# ESP32-P4 register map
Vendor: ESPRESSIF SYSTEMS (SHANGHAI) CO., LTD.; Series: ESP32 P-Series; File version: 3
CPU: RV32IMAFC r0p0, little endian, no MPU, FPU, 0 interrupt priority bits
Address unit: 32 bits
Registers are 32-bit, read-write, reset 0x0 unless marked. A register's access mark holds for its fields unless they carry their own. Offsets are from the block's base; [hi:lo] are bit positions; {n}, {i} and the like mark numbered series.

## INTERRUPT_CORE0 — Interrupt Controller (Core 0)
Base 0x500D6000
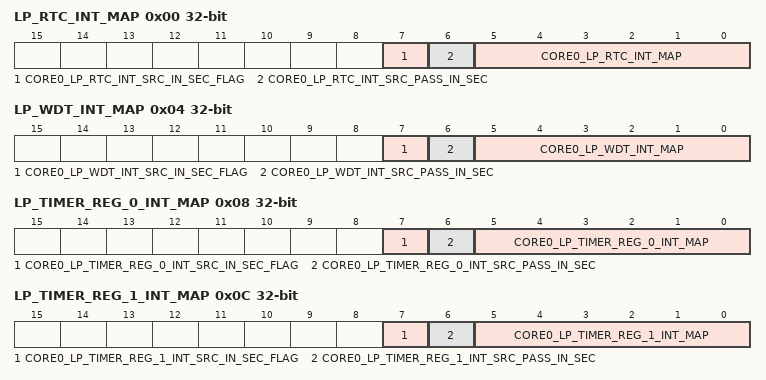
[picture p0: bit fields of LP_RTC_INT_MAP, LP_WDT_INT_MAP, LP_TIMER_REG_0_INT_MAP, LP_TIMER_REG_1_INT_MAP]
0x00 LP_RTC_INT_MAP
  [7] CORE0_LP_RTC_INT_SRC_IN_SEC_FLAG
  [6] CORE0_LP_RTC_INT_SRC_PASS_IN_SEC
  [5:0] CORE0_LP_RTC_INT_MAP — Configures the interrupt source into one CPU interrupt.
0x04 LP_WDT_INT_MAP
  [7] CORE0_LP_WDT_INT_SRC_IN_SEC_FLAG
  [6] CORE0_LP_WDT_INT_SRC_PASS_IN_SEC
  [5:0] CORE0_LP_WDT_INT_MAP — Configures the interrupt source into one CPU interrupt.
0x08 LP_TIMER_REG_0_INT_MAP
  [7] CORE0_LP_TIMER_REG_0_INT_SRC_IN_SEC_FLAG
  [6] CORE0_LP_TIMER_REG_0_INT_SRC_PASS_IN_SEC
  [5:0] CORE0_LP_TIMER_REG_0_INT_MAP — Configures the interrupt source into one CPU interrupt.
0x0C LP_TIMER_REG_1_INT_MAP
  [7] CORE0_LP_TIMER_REG_1_INT_SRC_IN_SEC_FLAG
  [6] CORE0_LP_TIMER_REG_1_INT_SRC_PASS_IN_SEC
  [5:0] CORE0_LP_TIMER_REG_1_INT_MAP — Configures the interrupt source into one CPU interrupt.
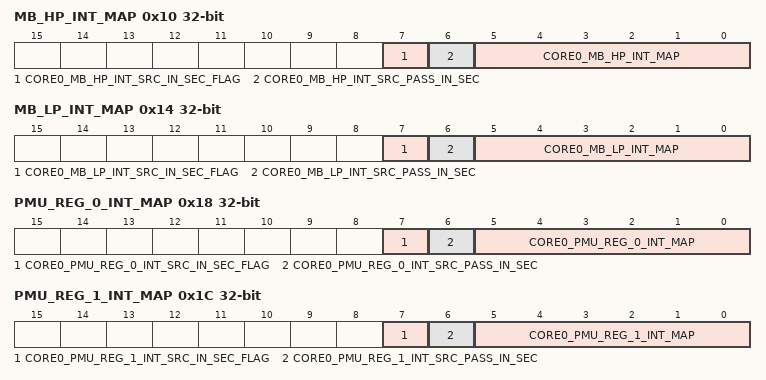
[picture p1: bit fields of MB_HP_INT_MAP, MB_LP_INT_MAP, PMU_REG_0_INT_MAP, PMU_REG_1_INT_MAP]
0x10 MB_HP_INT_MAP
  [7] CORE0_MB_HP_INT_SRC_IN_SEC_FLAG
  [6] CORE0_MB_HP_INT_SRC_PASS_IN_SEC
  [5:0] CORE0_MB_HP_INT_MAP — Configures the interrupt source into one CPU interrupt.
0x14 MB_LP_INT_MAP
  [7] CORE0_MB_LP_INT_SRC_IN_SEC_FLAG
  [6] CORE0_MB_LP_INT_SRC_PASS_IN_SEC
  [5:0] CORE0_MB_LP_INT_MAP — Configures the interrupt source into one CPU interrupt.
0x18 PMU_REG_0_INT_MAP
  [7] CORE0_PMU_REG_0_INT_SRC_IN_SEC_FLAG
  [6] CORE0_PMU_REG_0_INT_SRC_PASS_IN_SEC
  [5:0] CORE0_PMU_REG_0_INT_MAP — Configures the interrupt source into one CPU interrupt.
0x1C PMU_REG_1_INT_MAP
  [7] CORE0_PMU_REG_1_INT_SRC_IN_SEC_FLAG
  [6] CORE0_PMU_REG_1_INT_SRC_PASS_IN_SEC
  [5:0] CORE0_PMU_REG_1_INT_MAP — Configures the interrupt source into one CPU interrupt.
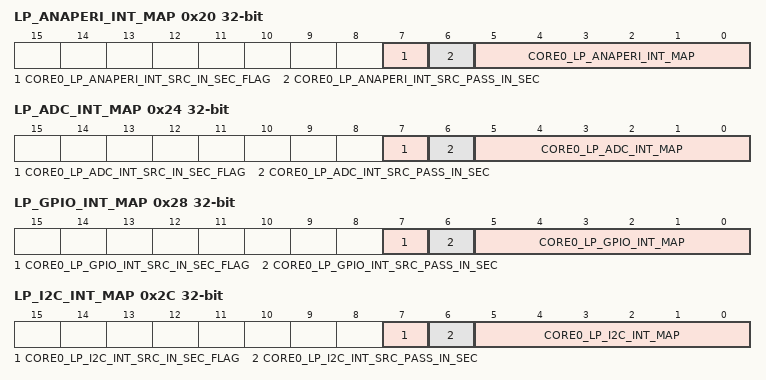
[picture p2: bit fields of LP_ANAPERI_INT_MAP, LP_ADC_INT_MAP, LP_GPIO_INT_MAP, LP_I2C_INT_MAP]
0x20 LP_ANAPERI_INT_MAP
  [7] CORE0_LP_ANAPERI_INT_SRC_IN_SEC_FLAG
  [6] CORE0_LP_ANAPERI_INT_SRC_PASS_IN_SEC
  [5:0] CORE0_LP_ANAPERI_INT_MAP — Configures the interrupt source into one CPU interrupt.
0x24 LP_ADC_INT_MAP
  [7] CORE0_LP_ADC_INT_SRC_IN_SEC_FLAG
  [6] CORE0_LP_ADC_INT_SRC_PASS_IN_SEC
  [5:0] CORE0_LP_ADC_INT_MAP — Configures the interrupt source into one CPU interrupt.
0x28 LP_GPIO_INT_MAP
  [7] CORE0_LP_GPIO_INT_SRC_IN_SEC_FLAG
  [6] CORE0_LP_GPIO_INT_SRC_PASS_IN_SEC
  [5:0] CORE0_LP_GPIO_INT_MAP — Configures the interrupt source into one CPU interrupt.
0x2C LP_I2C_INT_MAP
  [7] CORE0_LP_I2C_INT_SRC_IN_SEC_FLAG
  [6] CORE0_LP_I2C_INT_SRC_PASS_IN_SEC
  [5:0] CORE0_LP_I2C_INT_MAP — Configures the interrupt source into one CPU interrupt.
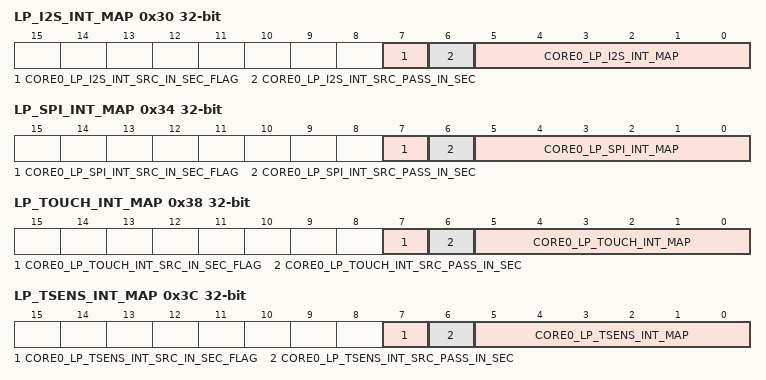
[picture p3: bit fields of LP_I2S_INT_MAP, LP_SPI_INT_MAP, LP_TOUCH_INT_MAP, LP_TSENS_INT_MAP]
0x30 LP_I2S_INT_MAP
  [7] CORE0_LP_I2S_INT_SRC_IN_SEC_FLAG
  [6] CORE0_LP_I2S_INT_SRC_PASS_IN_SEC
  [5:0] CORE0_LP_I2S_INT_MAP — Configures the interrupt source into one CPU interrupt.
0x34 LP_SPI_INT_MAP
  [7] CORE0_LP_SPI_INT_SRC_IN_SEC_FLAG
  [6] CORE0_LP_SPI_INT_SRC_PASS_IN_SEC
  [5:0] CORE0_LP_SPI_INT_MAP — Configures the interrupt source into one CPU interrupt.
0x38 LP_TOUCH_INT_MAP
  [7] CORE0_LP_TOUCH_INT_SRC_IN_SEC_FLAG
  [6] CORE0_LP_TOUCH_INT_SRC_PASS_IN_SEC
  [5:0] CORE0_LP_TOUCH_INT_MAP — Configures the interrupt source into one CPU interrupt.
0x3C LP_TSENS_INT_MAP
  [7] CORE0_LP_TSENS_INT_SRC_IN_SEC_FLAG
  [6] CORE0_LP_TSENS_INT_SRC_PASS_IN_SEC
  [5:0] CORE0_LP_TSENS_INT_MAP — Configures the interrupt source into one CPU interrupt.
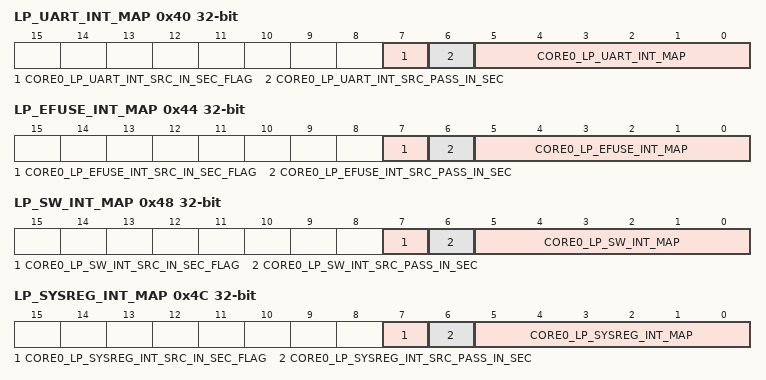
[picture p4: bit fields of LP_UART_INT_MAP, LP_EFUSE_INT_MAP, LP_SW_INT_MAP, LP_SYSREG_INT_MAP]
0x40 LP_UART_INT_MAP
  [7] CORE0_LP_UART_INT_SRC_IN_SEC_FLAG
  [6] CORE0_LP_UART_INT_SRC_PASS_IN_SEC
  [5:0] CORE0_LP_UART_INT_MAP — Configures the interrupt source into one CPU interrupt.
0x44 LP_EFUSE_INT_MAP
  [7] CORE0_LP_EFUSE_INT_SRC_IN_SEC_FLAG
  [6] CORE0_LP_EFUSE_INT_SRC_PASS_IN_SEC
  [5:0] CORE0_LP_EFUSE_INT_MAP — Configures the interrupt source into one CPU interrupt.
0x48 LP_SW_INT_MAP
  [7] CORE0_LP_SW_INT_SRC_IN_SEC_FLAG
  [6] CORE0_LP_SW_INT_SRC_PASS_IN_SEC
  [5:0] CORE0_LP_SW_INT_MAP — Configures the interrupt source into one CPU interrupt.
0x4C LP_SYSREG_INT_MAP
  [7] CORE0_LP_SYSREG_INT_SRC_IN_SEC_FLAG
  [6] CORE0_LP_SYSREG_INT_SRC_PASS_IN_SEC
  [5:0] CORE0_LP_SYSREG_INT_MAP — Configures the interrupt source into one CPU interrupt.
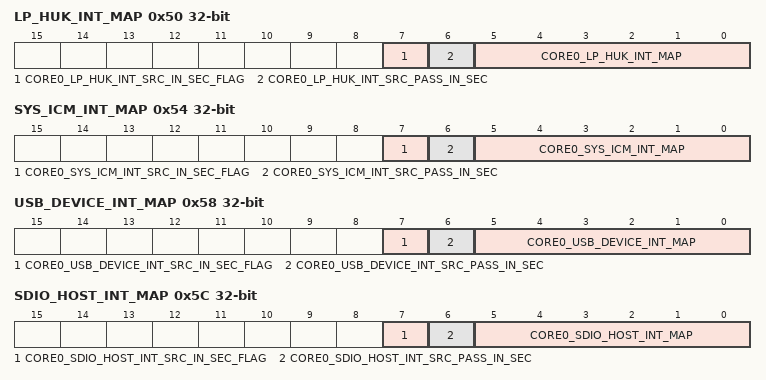
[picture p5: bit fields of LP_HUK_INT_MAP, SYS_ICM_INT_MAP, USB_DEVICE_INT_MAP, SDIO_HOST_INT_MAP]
0x50 LP_HUK_INT_MAP
  [7] CORE0_LP_HUK_INT_SRC_IN_SEC_FLAG
  [6] CORE0_LP_HUK_INT_SRC_PASS_IN_SEC
  [5:0] CORE0_LP_HUK_INT_MAP — Configures the interrupt source into one CPU interrupt.
0x54 SYS_ICM_INT_MAP
  [7] CORE0_SYS_ICM_INT_SRC_IN_SEC_FLAG
  [6] CORE0_SYS_ICM_INT_SRC_PASS_IN_SEC
  [5:0] CORE0_SYS_ICM_INT_MAP — Configures the interrupt source into one CPU interrupt.
0x58 USB_DEVICE_INT_MAP
  [7] CORE0_USB_DEVICE_INT_SRC_IN_SEC_FLAG
  [6] CORE0_USB_DEVICE_INT_SRC_PASS_IN_SEC
  [5:0] CORE0_USB_DEVICE_INT_MAP — Configures the interrupt source into one CPU interrupt.
0x5C SDIO_HOST_INT_MAP
  [7] CORE0_SDIO_HOST_INT_SRC_IN_SEC_FLAG
  [6] CORE0_SDIO_HOST_INT_SRC_PASS_IN_SEC
  [5:0] CORE0_SDIO_HOST_INT_MAP — Configures the interrupt source into one CPU interrupt.
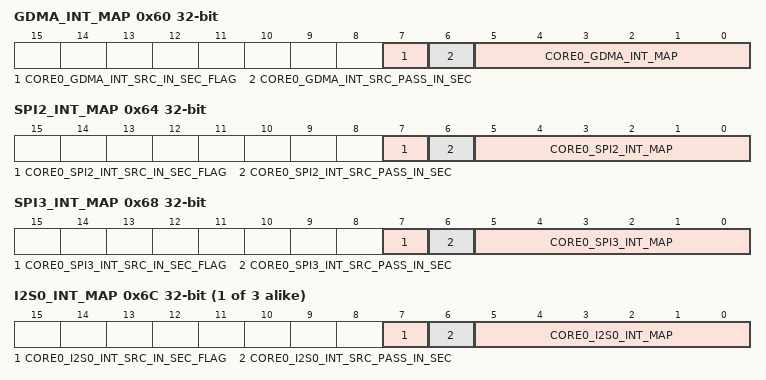
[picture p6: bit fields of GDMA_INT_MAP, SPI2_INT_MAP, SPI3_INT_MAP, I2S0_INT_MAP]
0x60 GDMA_INT_MAP
  [7] CORE0_GDMA_INT_SRC_IN_SEC_FLAG
  [6] CORE0_GDMA_INT_SRC_PASS_IN_SEC
  [5:0] CORE0_GDMA_INT_MAP — Configures the interrupt source into one CPU interrupt.
0x64 SPI2_INT_MAP
  [7] CORE0_SPI2_INT_SRC_IN_SEC_FLAG
  [6] CORE0_SPI2_INT_SRC_PASS_IN_SEC
  [5:0] CORE0_SPI2_INT_MAP — Configures the interrupt source into one CPU interrupt.
0x68 SPI3_INT_MAP
  [7] CORE0_SPI3_INT_SRC_IN_SEC_FLAG
  [6] CORE0_SPI3_INT_SRC_PASS_IN_SEC
  [5:0] CORE0_SPI3_INT_MAP — Configures the interrupt source into one CPU interrupt.
{0x6C+4i} I2S{i}_INT_MAP (i=0..2)
  [7] CORE0_I2S{i}_INT_SRC_IN_SEC_FLAG
  [6] CORE0_I2S{i}_INT_SRC_PASS_IN_SEC
  [5:0] CORE0_I2S{i}_INT_MAP — Configures the interrupt source into one CPU interrupt.
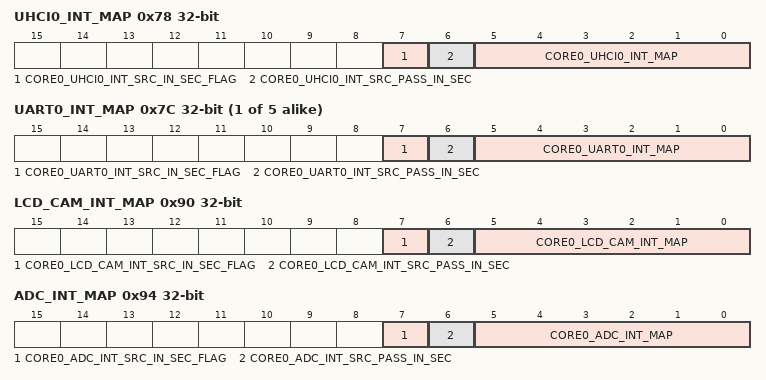
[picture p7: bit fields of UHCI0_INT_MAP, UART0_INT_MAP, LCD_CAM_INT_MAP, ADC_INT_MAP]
0x78 UHCI0_INT_MAP
  [7] CORE0_UHCI0_INT_SRC_IN_SEC_FLAG
  [6] CORE0_UHCI0_INT_SRC_PASS_IN_SEC
  [5:0] CORE0_UHCI0_INT_MAP — Configures the interrupt source into one CPU interrupt.
{0x7C+4i} UART{i}_INT_MAP (i=0..4)
  [7] CORE0_UART{i}_INT_SRC_IN_SEC_FLAG
  [6] CORE0_UART{i}_INT_SRC_PASS_IN_SEC
  [5:0] CORE0_UART{i}_INT_MAP — Configures the interrupt source into one CPU interrupt.
0x90 LCD_CAM_INT_MAP
  [7] CORE0_LCD_CAM_INT_SRC_IN_SEC_FLAG
  [6] CORE0_LCD_CAM_INT_SRC_PASS_IN_SEC
  [5:0] CORE0_LCD_CAM_INT_MAP — Configures the interrupt source into one CPU interrupt.
0x94 ADC_INT_MAP
  [7] CORE0_ADC_INT_SRC_IN_SEC_FLAG
  [6] CORE0_ADC_INT_SRC_PASS_IN_SEC
  [5:0] CORE0_ADC_INT_MAP — Configures the interrupt source into one CPU interrupt.
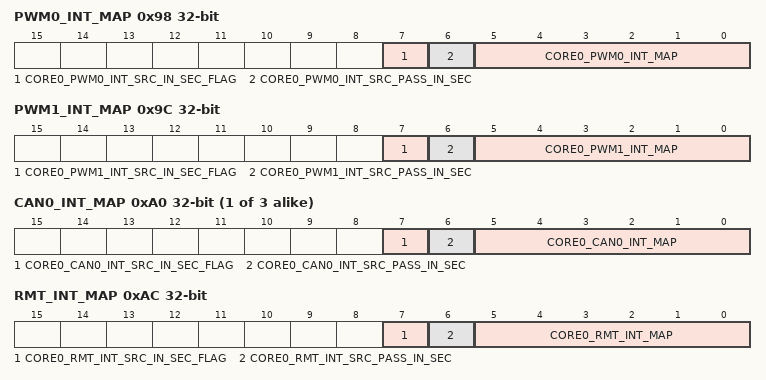
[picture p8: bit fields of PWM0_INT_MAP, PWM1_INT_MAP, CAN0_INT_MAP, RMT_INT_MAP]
0x98 PWM0_INT_MAP
  [7] CORE0_PWM0_INT_SRC_IN_SEC_FLAG
  [6] CORE0_PWM0_INT_SRC_PASS_IN_SEC
  [5:0] CORE0_PWM0_INT_MAP — Configures the interrupt source into one CPU interrupt.
0x9C PWM1_INT_MAP
  [7] CORE0_PWM1_INT_SRC_IN_SEC_FLAG
  [6] CORE0_PWM1_INT_SRC_PASS_IN_SEC
  [5:0] CORE0_PWM1_INT_MAP — Configures the interrupt source into one CPU interrupt.
{0xA0+4i} CAN{i}_INT_MAP (i=0..2)
  [7] CORE0_CAN{i}_INT_SRC_IN_SEC_FLAG
  [6] CORE0_CAN{i}_INT_SRC_PASS_IN_SEC
  [5:0] CORE0_CAN{i}_INT_MAP — Configures the interrupt source into one CPU interrupt.
0xAC RMT_INT_MAP
  [7] CORE0_RMT_INT_SRC_IN_SEC_FLAG
  [6] CORE0_RMT_INT_SRC_PASS_IN_SEC
  [5:0] CORE0_RMT_INT_MAP — Configures the interrupt source into one CPU interrupt.
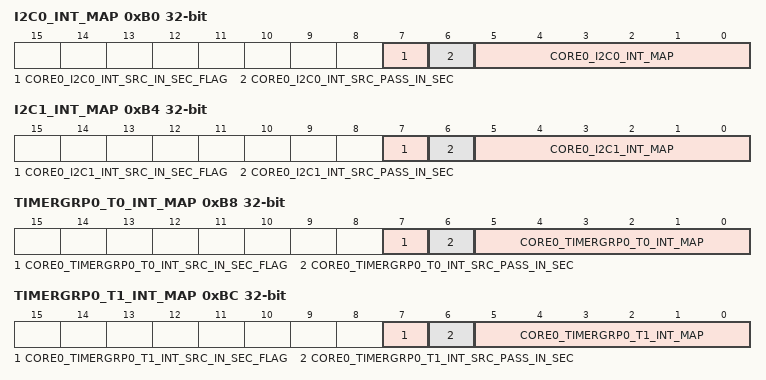
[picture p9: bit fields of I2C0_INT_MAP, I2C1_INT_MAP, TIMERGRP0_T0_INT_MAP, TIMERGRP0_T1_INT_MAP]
0xB0 I2C0_INT_MAP
  [7] CORE0_I2C0_INT_SRC_IN_SEC_FLAG
  [6] CORE0_I2C0_INT_SRC_PASS_IN_SEC
  [5:0] CORE0_I2C0_INT_MAP — Configures the interrupt source into one CPU interrupt.
0xB4 I2C1_INT_MAP
  [7] CORE0_I2C1_INT_SRC_IN_SEC_FLAG
  [6] CORE0_I2C1_INT_SRC_PASS_IN_SEC
  [5:0] CORE0_I2C1_INT_MAP — Configures the interrupt source into one CPU interrupt.
0xB8 TIMERGRP0_T0_INT_MAP
  [7] CORE0_TIMERGRP0_T0_INT_SRC_IN_SEC_FLAG
  [6] CORE0_TIMERGRP0_T0_INT_SRC_PASS_IN_SEC
  [5:0] CORE0_TIMERGRP0_T0_INT_MAP — Configures the interrupt source into one CPU interrupt.
0xBC TIMERGRP0_T1_INT_MAP
  [7] CORE0_TIMERGRP0_T1_INT_SRC_IN_SEC_FLAG
  [6] CORE0_TIMERGRP0_T1_INT_SRC_PASS_IN_SEC
  [5:0] CORE0_TIMERGRP0_T1_INT_MAP — Configures the interrupt source into one CPU interrupt.
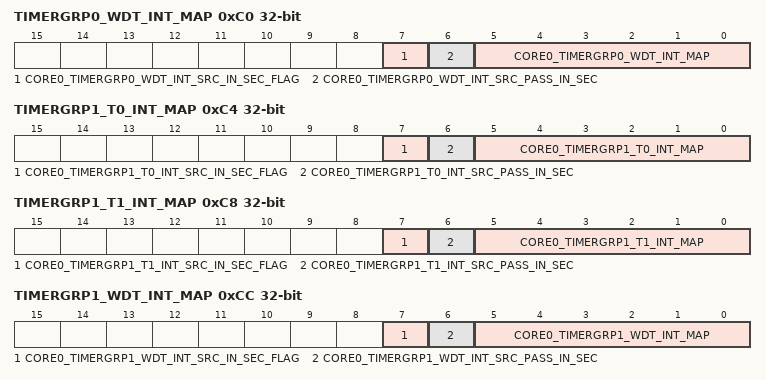
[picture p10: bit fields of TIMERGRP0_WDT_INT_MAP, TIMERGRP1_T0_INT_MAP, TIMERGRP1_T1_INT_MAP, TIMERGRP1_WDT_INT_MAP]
0xC0 TIMERGRP0_WDT_INT_MAP
  [7] CORE0_TIMERGRP0_WDT_INT_SRC_IN_SEC_FLAG
  [6] CORE0_TIMERGRP0_WDT_INT_SRC_PASS_IN_SEC
  [5:0] CORE0_TIMERGRP0_WDT_INT_MAP — Configures the interrupt source into one CPU interrupt.
0xC4 TIMERGRP1_T0_INT_MAP
  [7] CORE0_TIMERGRP1_T0_INT_SRC_IN_SEC_FLAG
  [6] CORE0_TIMERGRP1_T0_INT_SRC_PASS_IN_SEC
  [5:0] CORE0_TIMERGRP1_T0_INT_MAP — Configures the interrupt source into one CPU interrupt.
0xC8 TIMERGRP1_T1_INT_MAP
  [7] CORE0_TIMERGRP1_T1_INT_SRC_IN_SEC_FLAG
  [6] CORE0_TIMERGRP1_T1_INT_SRC_PASS_IN_SEC
  [5:0] CORE0_TIMERGRP1_T1_INT_MAP — Configures the interrupt source into one CPU interrupt.
0xCC TIMERGRP1_WDT_INT_MAP
  [7] CORE0_TIMERGRP1_WDT_INT_SRC_IN_SEC_FLAG
  [6] CORE0_TIMERGRP1_WDT_INT_SRC_PASS_IN_SEC
  [5:0] CORE0_TIMERGRP1_WDT_INT_MAP — Configures the interrupt source into one CPU interrupt.
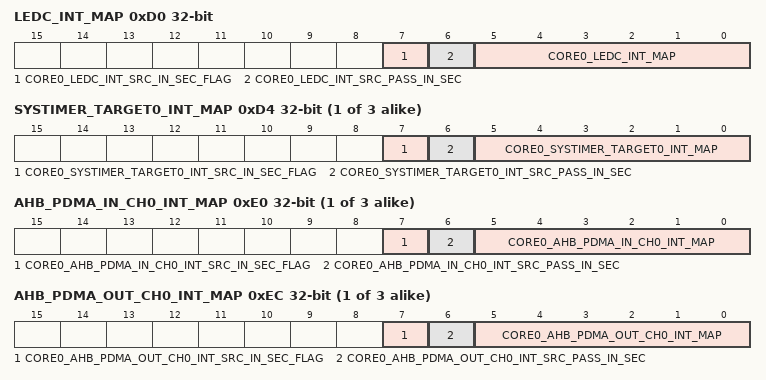
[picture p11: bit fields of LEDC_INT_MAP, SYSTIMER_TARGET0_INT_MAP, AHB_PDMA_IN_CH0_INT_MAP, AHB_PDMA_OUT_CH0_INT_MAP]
0xD0 LEDC_INT_MAP
  [7] CORE0_LEDC_INT_SRC_IN_SEC_FLAG
  [6] CORE0_LEDC_INT_SRC_PASS_IN_SEC
  [5:0] CORE0_LEDC_INT_MAP — Configures the interrupt source into one CPU interrupt.
{0xD4+4i} SYSTIMER_TARGET{i}_INT_MAP (i=0..2)
  [7] CORE0_SYSTIMER_TARGET{i}_INT_SRC_IN_SEC_FLAG
  [6] CORE0_SYSTIMER_TARGET{i}_INT_SRC_PASS_IN_SEC
  [5:0] CORE0_SYSTIMER_TARGET{i}_INT_MAP — Configures the interrupt source into one CPU interrupt.
{0xE0+4i} AHB_PDMA_IN_CH{i}_INT_MAP (i=0..2)
  [7] CORE0_AHB_PDMA_IN_CH{i}_INT_SRC_IN_SEC_FLAG
  [6] CORE0_AHB_PDMA_IN_CH{i}_INT_SRC_PASS_IN_SEC
  [5:0] CORE0_AHB_PDMA_IN_CH{i}_INT_MAP — Configures the interrupt source into one CPU interrupt.
{0xEC+4i} AHB_PDMA_OUT_CH{i}_INT_MAP (i=0..2)
  [7] CORE0_AHB_PDMA_OUT_CH{i}_INT_SRC_IN_SEC_FLAG
  [6] CORE0_AHB_PDMA_OUT_CH{i}_INT_SRC_PASS_IN_SEC
  [5:0] CORE0_AHB_PDMA_OUT_CH{i}_INT_MAP — Configures the interrupt source into one CPU interrupt.
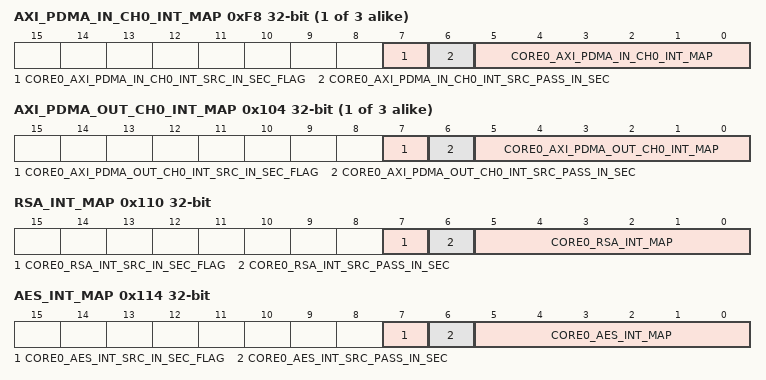
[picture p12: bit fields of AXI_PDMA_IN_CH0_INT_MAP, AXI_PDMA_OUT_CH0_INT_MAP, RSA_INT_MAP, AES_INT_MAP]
{0xF8+4i} AXI_PDMA_IN_CH{i}_INT_MAP (i=0..2)
  [7] CORE0_AXI_PDMA_IN_CH{i}_INT_SRC_IN_SEC_FLAG
  [6] CORE0_AXI_PDMA_IN_CH{i}_INT_SRC_PASS_IN_SEC
  [5:0] CORE0_AXI_PDMA_IN_CH{i}_INT_MAP — Configures the interrupt source into one CPU interrupt.
{0x104+4i} AXI_PDMA_OUT_CH{i}_INT_MAP (i=0..2)
  [7] CORE0_AXI_PDMA_OUT_CH{i}_INT_SRC_IN_SEC_FLAG
  [6] CORE0_AXI_PDMA_OUT_CH{i}_INT_SRC_PASS_IN_SEC
  [5:0] CORE0_AXI_PDMA_OUT_CH{i}_INT_MAP — Configures the interrupt source into one CPU interrupt.
0x110 RSA_INT_MAP
  [7] CORE0_RSA_INT_SRC_IN_SEC_FLAG
  [6] CORE0_RSA_INT_SRC_PASS_IN_SEC
  [5:0] CORE0_RSA_INT_MAP — Configures the interrupt source into one CPU interrupt.
0x114 AES_INT_MAP
  [7] CORE0_AES_INT_SRC_IN_SEC_FLAG
  [6] CORE0_AES_INT_SRC_PASS_IN_SEC
  [5:0] CORE0_AES_INT_MAP — Configures the interrupt source into one CPU interrupt.
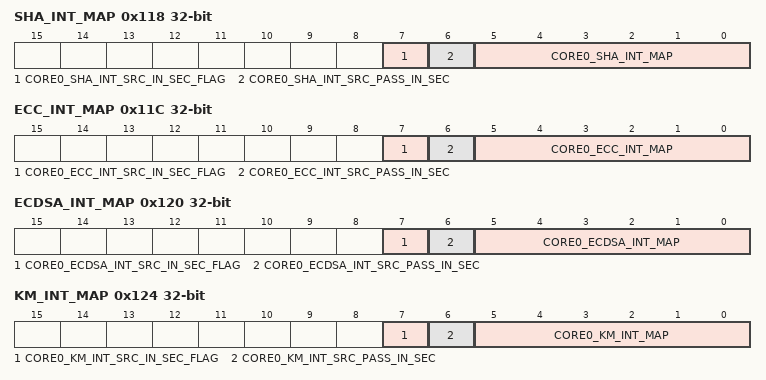
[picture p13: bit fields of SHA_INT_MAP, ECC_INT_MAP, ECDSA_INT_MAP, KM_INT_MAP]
0x118 SHA_INT_MAP
  [7] CORE0_SHA_INT_SRC_IN_SEC_FLAG
  [6] CORE0_SHA_INT_SRC_PASS_IN_SEC
  [5:0] CORE0_SHA_INT_MAP — Configures the interrupt source into one CPU interrupt.
0x11C ECC_INT_MAP
  [7] CORE0_ECC_INT_SRC_IN_SEC_FLAG
  [6] CORE0_ECC_INT_SRC_PASS_IN_SEC
  [5:0] CORE0_ECC_INT_MAP — Configures the interrupt source into one CPU interrupt.
0x120 ECDSA_INT_MAP
  [7] CORE0_ECDSA_INT_SRC_IN_SEC_FLAG
  [6] CORE0_ECDSA_INT_SRC_PASS_IN_SEC
  [5:0] CORE0_ECDSA_INT_MAP — Configures the interrupt source into one CPU interrupt.
0x124 KM_INT_MAP
  [7] CORE0_KM_INT_SRC_IN_SEC_FLAG
  [6] CORE0_KM_INT_SRC_PASS_IN_SEC
  [5:0] CORE0_KM_INT_MAP — Configures the interrupt source into one CPU interrupt.
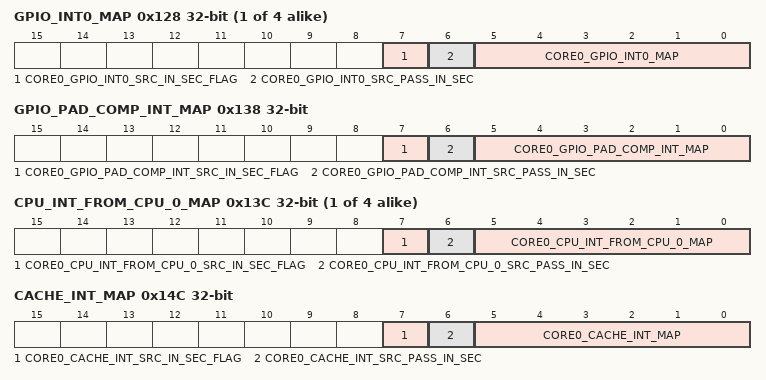
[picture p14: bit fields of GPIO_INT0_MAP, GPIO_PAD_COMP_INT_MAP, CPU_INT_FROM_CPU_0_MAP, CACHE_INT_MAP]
{0x128+4i} GPIO_INT{i}_MAP (i=0..3)
  [7] CORE0_GPIO_INT{i}_SRC_IN_SEC_FLAG
  [6] CORE0_GPIO_INT{i}_SRC_PASS_IN_SEC
  [5:0] CORE0_GPIO_INT{i}_MAP — Configures the interrupt source into one CPU interrupt.
0x138 GPIO_PAD_COMP_INT_MAP
  [7] CORE0_GPIO_PAD_COMP_INT_SRC_IN_SEC_FLAG
  [6] CORE0_GPIO_PAD_COMP_INT_SRC_PASS_IN_SEC
  [5:0] CORE0_GPIO_PAD_COMP_INT_MAP — Configures the interrupt source into one CPU interrupt.
{0x13C+4i} CPU_INT_FROM_CPU_{i}_MAP (i=0..3)
  [7] CORE0_CPU_INT_FROM_CPU_{i}_SRC_IN_SEC_FLAG
  [6] CORE0_CPU_INT_FROM_CPU_{i}_SRC_PASS_IN_SEC
  [5:0] CORE0_CPU_INT_FROM_CPU_{i}_MAP — Configures the interrupt source into one CPU interrupt.
0x14C CACHE_INT_MAP
  [7] CORE0_CACHE_INT_SRC_IN_SEC_FLAG
  [6] CORE0_CACHE_INT_SRC_PASS_IN_SEC
  [5:0] CORE0_CACHE_INT_MAP — Configures the interrupt source into one CPU interrupt.
0x150 FLASH_MSPI_INT_MAP
  [7] CORE0_FLASH_MSPI_INT_SRC_IN_SEC_FLAG
  [6] CORE0_FLASH_MSPI_INT_SRC_PASS_IN_SEC
  [5:0] CORE0_FLASH_MSPI_INT_MAP — Configures the interrupt source into one CPU interrupt.
0x154 CSI_BRIDGE_INT_MAP
  [7] CORE0_CSI_BRIDGE_INT_SRC_IN_SEC_FLAG
  [6] CORE0_CSI_BRIDGE_INT_SRC_PASS_IN_SEC
  [5:0] CORE0_CSI_BRIDGE_INT_MAP — Configures the interrupt source into one CPU interrupt.
0x158 DSI_BRIDGE_INT_MAP
  [7] CORE0_DSI_BRIDGE_INT_SRC_IN_SEC_FLAG
  [6] CORE0_DSI_BRIDGE_INT_SRC_PASS_IN_SEC
  [5:0] CORE0_DSI_BRIDGE_INT_MAP — Configures the interrupt source into one CPU interrupt.
0x15C CSI_INT_MAP
  [7] CORE0_CSI_INT_SRC_IN_SEC_FLAG
  [6] CORE0_CSI_INT_SRC_PASS_IN_SEC
  [5:0] CORE0_CSI_INT_MAP — Configures the interrupt source into one CPU interrupt.
0x160 DSI_INT_MAP
  [7] CORE0_DSI_INT_SRC_IN_SEC_FLAG
  [6] CORE0_DSI_INT_SRC_PASS_IN_SEC
  [5:0] CORE0_DSI_INT_MAP — Configures the interrupt source into one CPU interrupt.
0x164 GMII_PHY_INT_MAP
  [7] CORE0_GMII_PHY_INT_SRC_IN_SEC_FLAG
  [6] CORE0_GMII_PHY_INT_SRC_PASS_IN_SEC
  [5:0] CORE0_GMII_PHY_INT_MAP — Configures the interrupt source into one CPU interrupt.
0x168 LPI_INT_MAP
  [7] CORE0_LPI_INT_SRC_IN_SEC_FLAG
  [6] CORE0_LPI_INT_SRC_PASS_IN_SEC
  [5:0] CORE0_LPI_INT_MAP — Configures the interrupt source into one CPU interrupt.
0x16C PMT_INT_MAP
  [7] CORE0_PMT_INT_SRC_IN_SEC_FLAG
  [6] CORE0_PMT_INT_SRC_PASS_IN_SEC
  [5:0] CORE0_PMT_INT_MAP — Configures the interrupt source into one CPU interrupt.
0x170 SBD_INT_MAP
  [7] CORE0_SBD_INT_SRC_IN_SEC_FLAG
  [6] CORE0_SBD_INT_SRC_PASS_IN_SEC
  [5:0] CORE0_SBD_INT_MAP — Configures the interrupt source into one CPU interrupt.
0x174 USB_OTG_INT_MAP
  [7] CORE0_USB_OTG_INT_SRC_IN_SEC_FLAG
  [6] CORE0_USB_OTG_INT_SRC_PASS_IN_SEC
  [5:0] CORE0_USB_OTG_INT_MAP — Configures the interrupt source into one CPU interrupt.
0x178 USB_OTG_ENDP_MULTI_PROC_INT_MAP
  [7] CORE0_USB_OTG_ENDP_MULTI_PROC_INT_SRC_IN_SEC_FLAG
  [6] CORE0_USB_OTG_ENDP_MULTI_PROC_INT_SRC_PASS_IN_SEC
  [5:0] CORE0_USB_OTG_ENDP_MULTI_PROC_INT_MAP — Configures the interrupt source into one CPU interrupt.
0x17C JPEG_INT_MAP
  [7] CORE0_JPEG_INT_SRC_IN_SEC_FLAG
  [6] CORE0_JPEG_INT_SRC_PASS_IN_SEC
  [5:0] CORE0_JPEG_INT_MAP — Configures the interrupt source into one CPU interrupt.
0x180 PPA_INT_MAP
  [7] CORE0_PPA_INT_SRC_IN_SEC_FLAG
  [6] CORE0_PPA_INT_SRC_PASS_IN_SEC
  [5:0] CORE0_PPA_INT_MAP — Configures the interrupt source into one CPU interrupt.
0x184 CORE0_TRACE_INT_MAP
  [7] CORE0_CORE0_TRACE_INT_SRC_IN_SEC_FLAG
  [6] CORE0_CORE0_TRACE_INT_SRC_PASS_IN_SEC
  [5:0] CORE0_CORE0_TRACE_INT_MAP — Configures the interrupt source into one CPU interrupt.
0x188 CORE1_TRACE_INT_MAP
  [7] CORE0_CORE1_TRACE_INT_SRC_IN_SEC_FLAG
  [6] CORE0_CORE1_TRACE_INT_SRC_PASS_IN_SEC
  [5:0] CORE0_CORE1_TRACE_INT_MAP — Configures the interrupt source into one CPU interrupt.
0x18C HP_CORE_CTRL_INT_MAP
  [7] CORE0_HP_CORE_CTRL_INT_SRC_IN_SEC_FLAG
  [6] CORE0_HP_CORE_CTRL_INT_SRC_PASS_IN_SEC
  [5:0] CORE0_HP_CORE_CTRL_INT_MAP — Configures the interrupt source into one CPU interrupt.
0x190 ISP_INT_MAP
  [7] CORE0_ISP_INT_SRC_IN_SEC_FLAG
  [6] CORE0_ISP_INT_SRC_PASS_IN_SEC
  [5:0] CORE0_ISP_INT_MAP — Configures the interrupt source into one CPU interrupt.
0x194 I3C_MST_INT_MAP
  [7] CORE0_I3C_MST_INT_SRC_IN_SEC_FLAG
  [6] CORE0_I3C_MST_INT_SRC_PASS_IN_SEC
  [5:0] CORE0_I3C_MST_INT_MAP — Configures the interrupt source into one CPU interrupt.
0x198 I3C_SLV_INT_MAP
  [7] CORE0_I3C_SLV_INT_SRC_IN_SEC_FLAG
  [6] CORE0_I3C_SLV_INT_SRC_PASS_IN_SEC
  [5:0] CORE0_I3C_SLV_INT_MAP — Configures the interrupt source into one CPU interrupt.
0x19C USB_OTG11_INT_MAP
  [7] CORE0_USB_OTG11_INT_SRC_IN_SEC_FLAG
  [6] CORE0_USB_OTG11_INT_SRC_PASS_IN_SEC
  [5:0] CORE0_USB_OTG11_INT_MAP — Configures the interrupt source into one CPU interrupt.
0x1A0 DMA2D_IN_CH0_INT_MAP
  [7] CORE0_DMA2D_IN_CH0_INT_SRC_IN_SEC_FLAG
  [6] CORE0_DMA2D_IN_CH0_INT_SRC_PASS_IN_SEC
  [5:0] CORE0_DMA2D_IN_CH0_INT_MAP — Configures the interrupt source into one CPU interrupt.
0x1A4 DMA2D_IN_CH1_INT_MAP
  [7] CORE0_DMA2D_IN_CH1_INT_SRC_IN_SEC_FLAG
  [6] CORE0_DMA2D_IN_CH1_INT_SRC_PASS_IN_SEC
  [5:0] CORE0_DMA2D_IN_CH1_INT_MAP — Configures the interrupt source into one CPU interrupt.
{0x1A8+4i} DMA2D_OUT_CH{i}_INT_MAP (i=0..2)
  [7] CORE0_DMA2D_OUT_CH{i}_INT_SRC_IN_SEC_FLAG
  [6] CORE0_DMA2D_OUT_CH{i}_INT_SRC_PASS_IN_SEC
  [5:0] CORE0_DMA2D_OUT_CH{i}_INT_MAP — Configures the interrupt source into one CPU interrupt.
0x1B4 PSRAM_MSPI_INT_MAP
  [7] CORE0_PSRAM_MSPI_INT_SRC_IN_SEC_FLAG
  [6] CORE0_PSRAM_MSPI_INT_SRC_PASS_IN_SEC
  [5:0] CORE0_PSRAM_MSPI_INT_MAP — Configures the interrupt source into one CPU interrupt.
0x1B8 HP_SYSREG_INT_MAP
  [7] CORE0_HP_SYSREG_INT_SRC_IN_SEC_FLAG
  [6] CORE0_HP_SYSREG_INT_SRC_PASS_IN_SEC
  [5:0] CORE0_HP_SYSREG_INT_MAP — Configures the interrupt source into one CPU interrupt.
0x1BC PCNT_INT_MAP
  [7] CORE0_PCNT_INT_SRC_IN_SEC_FLAG
  [6] CORE0_PCNT_INT_SRC_PASS_IN_SEC
  [5:0] CORE0_PCNT_INT_MAP — Configures the interrupt source into one CPU interrupt.
0x1C0 HP_PAU_INT_MAP
  [7] CORE0_HP_PAU_INT_SRC_IN_SEC_FLAG
  [6] CORE0_HP_PAU_INT_SRC_PASS_IN_SEC
  [5:0] CORE0_HP_PAU_INT_MAP — Configures the interrupt source into one CPU interrupt.
0x1C4 HP_PARLIO_RX_INT_MAP
  [7] CORE0_HP_PARLIO_RX_INT_SRC_IN_SEC_FLAG
  [6] CORE0_HP_PARLIO_RX_INT_SRC_PASS_IN_SEC
  [5:0] CORE0_HP_PARLIO_RX_INT_MAP — Configures the interrupt source into one CPU interrupt.
0x1C8 HP_PARLIO_TX_INT_MAP
  [7] CORE0_HP_PARLIO_TX_INT_SRC_IN_SEC_FLAG
  [6] CORE0_HP_PARLIO_TX_INT_SRC_PASS_IN_SEC
  [5:0] CORE0_HP_PARLIO_TX_INT_MAP — Configures the interrupt source into one CPU interrupt.
{0x1CC+4i} H264_DMA2D_OUT_CH{i}_INT_MAP (i=0..4)
  [7] CORE0_H264_DMA2D_OUT_CH{i}_INT_SRC_IN_SEC_FLAG
  [6] CORE0_H264_DMA2D_OUT_CH{i}_INT_SRC_PASS_IN_SEC
  [5:0] CORE0_H264_DMA2D_OUT_CH{i}_INT_MAP — Configures the interrupt source into one CPU interrupt.
{0x1E0+4i} H264_DMA2D_IN_CH{i}_INT_MAP (i=0..5)
  [7] CORE0_H264_DMA2D_IN_CH{i}_INT_SRC_IN_SEC_FLAG
  [6] CORE0_H264_DMA2D_IN_CH{i}_INT_SRC_PASS_IN_SEC
  [5:0] CORE0_H264_DMA2D_IN_CH{i}_INT_MAP — Configures the interrupt source into one CPU interrupt.
0x1F8 H264_REG_INT_MAP
  [7] CORE0_H264_REG_INT_SRC_IN_SEC_FLAG
  [6] CORE0_H264_REG_INT_SRC_PASS_IN_SEC
  [5:0] CORE0_H264_REG_INT_MAP — Configures the interrupt source into one CPU interrupt.
0x1FC ASSIST_DEBUG_INT_MAP
  [7] CORE0_ASSIST_DEBUG_INT_SRC_IN_SEC_FLAG
  [6] CORE0_ASSIST_DEBUG_INT_SRC_PASS_IN_SEC
  [5:0] CORE0_ASSIST_DEBUG_INT_MAP — Configures the interrupt source into one CPU interrupt.
{0x200+4i} INTR_STATUS_REG_{i} ro (i=0..3)
  [31:0] CORE0_INTR_STATUS_{i}
0x210 CLOCK_GATE reset 0x1
  [0] CORE0_REG_CLK_EN
0x214 DMA2D_IN_CH2_INT_MAP
  [7] CORE0_DMA2D_IN_CH2_INT_SRC_IN_SEC_FLAG
  [6] CORE0_DMA2D_IN_CH2_INT_SRC_PASS_IN_SEC
  [5:0] CORE0_DMA2D_IN_CH2_INT_MAP — Configures the interrupt source into one CPU interrupt.
0x218 DMA2D_OUT_CH3_INT_MAP
  [7] CORE0_DMA2D_OUT_CH3_INT_SRC_IN_SEC_FLAG
  [6] CORE0_DMA2D_OUT_CH3_INT_SRC_PASS_IN_SEC
  [5:0] CORE0_DMA2D_OUT_CH3_INT_MAP — Configures the interrupt source into one CPU interrupt.
0x21C AXI_PERF_MON_INT_MAP
  [7] CORE0_AXI_PERF_MON_INT_SRC_IN_SEC_FLAG
  [6] CORE0_AXI_PERF_MON_INT_SRC_PASS_IN_SEC
  [5:0] CORE0_AXI_PERF_MON_INT_MAP — Configures the interrupt source into one CPU interrupt.
0x220 INTR_STATUS_REG_4 ro
  [31:0] CORE0_INTR_STATUS_4
0x228 INTR_SIG_IDX_ASSERT_IN_SEC
  [5:0] CORE0_INTR_SIG_IDX_ASSERT_IN_SEC
0x22C INTR_SEC_STATUS ro
  [31:0] CORE0_INTR_SEC_STATUS
{0x230+4i} INTR_SRC_PASS_IN_SEC_STATUS_{i} ro (i=0..4)
  [31:0] CORE0_INTR_SRC_PASS_IN_SEC_STATUS_{i}
0x3FC INTERRUPT_REG_DATE reset 0x2502280
  [27:0] CORE0_INTERRUPT_REG_DATE
